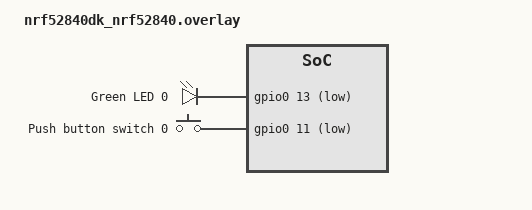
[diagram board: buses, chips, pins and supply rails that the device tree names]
#include <zephyr/dt-bindings/gpio/gpio.h>

/ {
    aliases {
        sw0 = &button0;
        led0 = &led0_green;
    };

    leds {
        compatible = "gpio-leds";
        led0_green: led_0 {
            gpios = <&gpio0 13 GPIO_ACTIVE_LOW>;
            label = "Green LED 0";
        };
    };

    buttons {
        compatible = "gpio-keys";
        button0: button_0 {
            gpios = <&gpio0 11 (GPIO_PULL_UP | GPIO_ACTIVE_LOW)>;
            label = "Push button switch 0";
        };
    };
};

&gpio0 {
    status = "okay";
};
